# ATSAML21G18A register map
Vendor: Microchip Technology Inc.; Series: SAML21; File version: A
CPU: CM0+ r0p1, little endian, no MPU, no FPU, VTOR, 2 interrupt priority bits, 29 interrupts
Registers are 32-bit, read-write, reset 0x0 unless marked. A register's access mark holds for its fields unless they carry their own. Offsets are from the block's base; [hi:lo] are bit positions; {n}, {i} and the like mark numbered series; 'fields as' and 'values as' point back to an identical list.

## EVSYS — Event System Interface
Base 0x43000000; register names take the prefix EVSYS_
0x00 CTRLA 8-bit — Control
  [0] SWRST wo — Software Reset
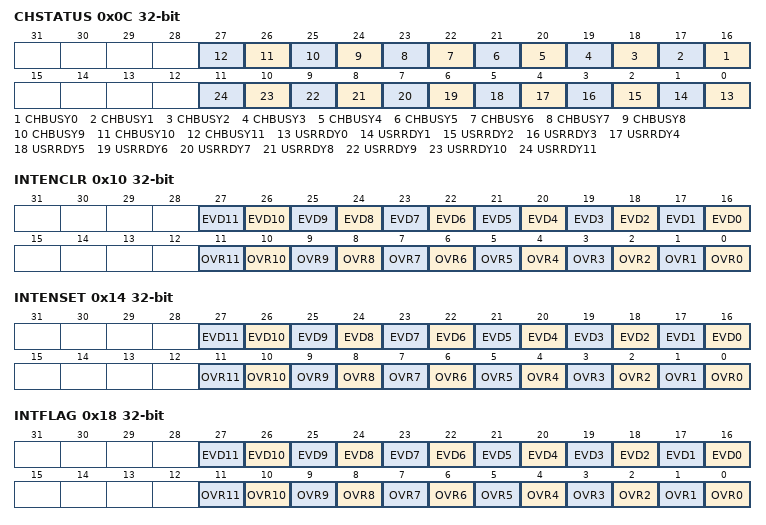
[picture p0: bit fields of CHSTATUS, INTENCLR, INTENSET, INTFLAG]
0x0C CHSTATUS ro — Channel Status
  [n+16] CHBUSY{n} (n=0..11) — Channel {n} Busy
  [n] USRRDY{n} (n=0..11) — Channel {n} User Ready
0x10 INTENCLR — Interrupt Enable Clear
  [n+16] EVD{n} (n=0..11) — Channel {n} Event Detection Interrupt Enable
  [n] OVR{n} (n=0..11) — Channel {n} Overrun Interrupt Enable
0x14 INTENSET — Interrupt Enable Set
  fields as INTENCLR
0x18 INTFLAG — Interrupt Flag Status and Clear
  [n+16] EVD{n} (n=0..11) — Channel {n} Event Detection
  [n] OVR{n} (n=0..11) — Channel {n} Overrun
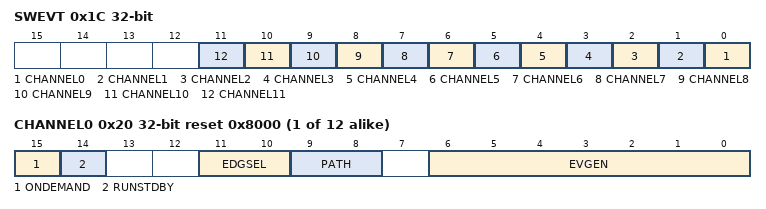
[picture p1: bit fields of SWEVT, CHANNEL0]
0x1C SWEVT wo — Software Event
  [n] CHANNEL{n} (n=0..11) — Channel {n} Software Selection
{0x20+4i} CHANNEL{i} (i=0..11) reset 0x8000 — Channel n
  [15] ONDEMAND — Generic Clock On Demand
  [14] RUNSTDBY — Run in standby
  [11:10] EDGSEL — Edge Detection Selection
    0=NO_EVT_OUTPUT (No event output when using the resynchronized or synchronous path); 1=RISING_EDGE (Event detection only on the rising edge of the signal from the event generator when using the resynchronized or synchronous path); 2=FALLING_EDGE (Event detection only on the falling edge of the signal from the event generator when using the resynchronized or synchronous path); 3=BOTH_EDGES (Event detection on rising and falling edges of the signal from the event generator when using the resynchronized or synchronous path)
  [9:8] PATH — Path Selection
    0=SYNCHRONOUS (Synchronous path); 1=RESYNCHRONIZED (Resynchronized path); 2=ASYNCHRONOUS (Asynchronous path)
  [6:0] EVGEN — Event Generator Selection
{0x80+4i} USER{i} (i=0..44) — User Multiplexer n
  [4:0] CHANNEL — Channel Event Selection

## GCLK — Generic Clock Generator
Base 0x40001800; register names take the prefix GCLK_
0x00 CTRLA 8-bit — Control
  [0] SWRST — Software Reset
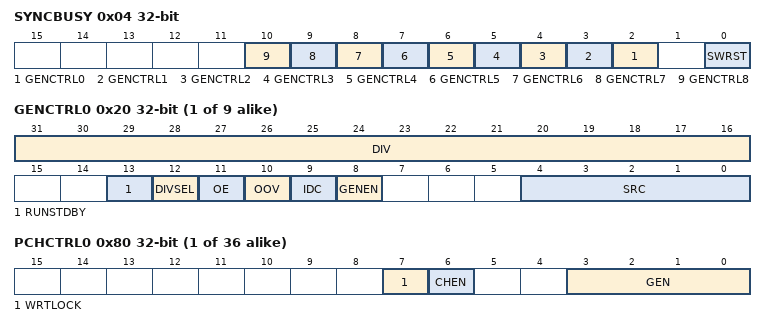
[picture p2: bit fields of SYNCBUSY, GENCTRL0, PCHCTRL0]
0x04 SYNCBUSY ro — Synchronization Busy
  [n+2] GENCTRL{n} (n=0..8) — Generic Clock Generator Control {n} Synchronization Busy bits
    1=GCLK0 (Generic clock generator 0); 2=GCLK1 (Generic clock generator 1); 4=GCLK2 (Generic clock generator 2); 8=GCLK3 (Generic clock generator 3); 16=GCLK4 (Generic clock generator 4); 32=GCLK5 (Generic clock generator 5); 64=GCLK6 (Generic clock generator 6); 128=GCLK7 (Generic clock generator 7); 0x100=GCLK8 (Generic clock generator 8)
  [0] SWRST — Software Reset Synchroniation Busy bit
{0x20+4i} GENCTRL{i} (i=0..8) — Generic Clock Generator Control
  [31:16] DIV — Division Factor
  [13] RUNSTDBY — Run in Standby
  [12] DIVSEL — Divide Selection
  [11] OE — Output Enable
  [10] OOV — Output Off Value
  [9] IDC — Improve Duty Cycle
  [8] GENEN — Generic Clock Generator Enable
  [4:0] SRC — Source Select
    0=XOSC (XOSC oscillator output); 1=GCLKIN (Generator input pad); 2=GCLKGEN1 (Generic clock generator 1 output); 3=OSCULP32K (OSCULP32K oscillator output); 4=OSC32K (OSC32K oscillator output); 5=XOSC32K (XOSC32K oscillator output); 6=OSC16M (OSC16M oscillator output); 7=DFLL48M (DFLL48M output); 8=DPLL96M (DPLL96M output)
{0x80+4i} PCHCTRL{i} (i=0..35) — Peripheral Clock Control
  [7] WRTLOCK — Write Lock
  [6] CHEN — Channel Enable
  [3:0] GEN — Generic Clock Generator
    {v}=GCLK{v} (Generic clock generator {v}) (v=0..8)

## MCLK — Main Clock
Base 0x40000400; register names take the prefix MCLK_
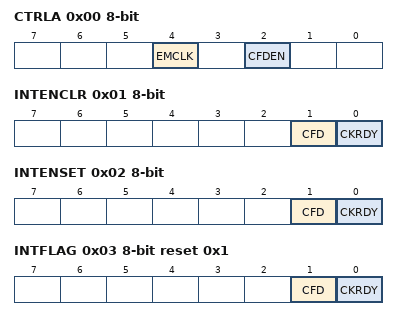
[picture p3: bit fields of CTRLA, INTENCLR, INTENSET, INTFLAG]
0x00 CTRLA 8-bit — Control A
  [4] EMCLK — Emergency Clock Select
  [2] CFDEN — Clock Failure Detector Enable
0x01 INTENCLR 8-bit — Interrupt Enable Clear
  [1] CFD — Clock Failure Detector Interrupt Enable
  [0] CKRDY — Clock Ready Interrupt Enable
0x02 INTENSET 8-bit — Interrupt Enable Set
  fields as INTENCLR
0x03 INTFLAG 8-bit reset 0x1 — Interrupt Flag Status and Clear
  [1] CFD — Clock Failure Detector
  [0] CKRDY — Clock Ready
0x04 CPUDIV 8-bit reset 0x1 — CPU Clock Division
  [7:0] CPUDIV — CPU Clock Division Factor
    1=DIV1 (Divide by 1); 2=DIV2 (Divide by 2); 4=DIV4 (Divide by 4); 8=DIV8 (Divide by 8); 16=DIV16 (Divide by 16); 32=DIV32 (Divide by 32); 64=DIV64 (Divide by 64); 128=DIV128 (Divide by 128)
0x05 LPDIV 8-bit reset 0x1 — Low-Power Clock Division
  [7:0] LPDIV — Low-Power Clock Division Factor
    values as CPUDIV.CPUDIV
0x06 BUPDIV 8-bit reset 0x1 — Backup Clock Division
  [7:0] BUPDIV — Backup Clock Division Factor
    values as CPUDIV.CPUDIV
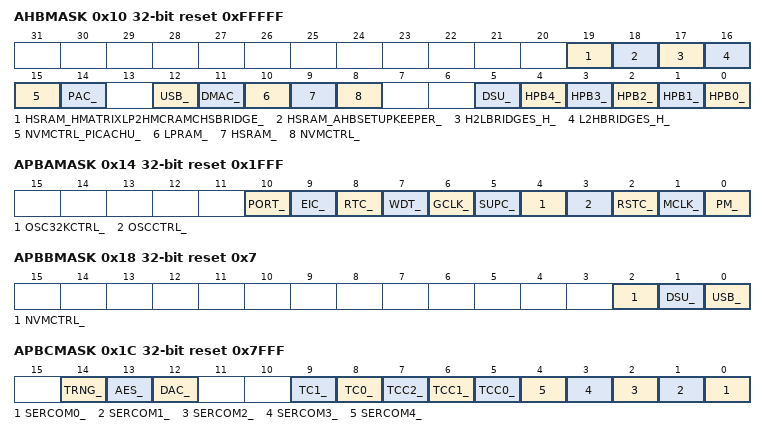
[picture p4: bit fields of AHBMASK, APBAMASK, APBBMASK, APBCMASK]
0x10 AHBMASK reset 0xFFFFF
  [19] HSRAM_HMATRIXLP2HMCRAMCHSBRIDGE_ — HSRAM_HMATRIXLP2HMCRAMCHSBRIDGE AHB Clock Mask
  [18] HSRAM_AHBSETUPKEEPER_ — HSRAM_AHBSETUPKEEPER AHB Clock Mask
  [17] H2LBRIDGES_H_ — H2LBRIDGES_H AHB Clock Mask
  [16] L2HBRIDGES_H_ — L2HBRIDGES_H AHB Clock Mask
  [15] NVMCTRL_PICACHU_ — NVMCTRL_PICACHU AHB Clock Mask
  [14] PAC_ — PAC AHB Clock Mask
  [12] USB_ — USB AHB Clock Mask
  [11] DMAC_ — DMAC AHB Clock Mask
  [10] LPRAM_ — LPRAM AHB Clock Mask
  [9] HSRAM_ — HSRAM AHB Clock Mask
  [8] NVMCTRL_ — NVMCTRL AHB Clock Mask
  [5] DSU_ — DSU AHB Clock Mask
  [n] HPB{n}_ (n=0..4) — HPB{n} AHB Clock Mask
0x14 APBAMASK reset 0x1FFF
  [10] PORT_ — PORT APB Clock Enable
  [9] EIC_ — EIC APB Clock Enable
  [8] RTC_ — RTC APB Clock Enable
  [7] WDT_ — WDT APB Clock Enable
  [6] GCLK_ — GCLK APB Clock Enable
  [5] SUPC_ — SUPC APB Clock Enable
  [4] OSC32KCTRL_ — OSC32KCTRL APB Clock Enable
  [3] OSCCTRL_ — OSCCTRL APB Clock Enable
  [2] RSTC_ — RSTC APB Clock Enable
  [1] MCLK_ — MCLK APB Clock Enable
  [0] PM_ — PM APB Clock Enable
0x18 APBBMASK reset 0x7
  [2] NVMCTRL_ — NVMCTRL APB Clock Enable
  [1] DSU_ — DSU APB Clock Enable
  [0] USB_ — USB APB Clock Enable
0x1C APBCMASK reset 0x7FFF
  [14] TRNG_ — TRNG APB Clock Enable
  [13] AES_ — AES APB Clock Enable
  [12] DAC_ — DAC APB Clock Enable
  [9] TC1_ — TC1 APB Clock Enable
  [8] TC0_ — TC0 APB Clock Enable
  [7] TCC2_ — TCC2 APB Clock Enable
  [6] TCC1_ — TCC1 APB Clock Enable
  [5] TCC0_ — TCC0 APB Clock Enable
  [n] SERCOM{n}_ (n=0..4) — SERCOM{n} APB Clock Enable
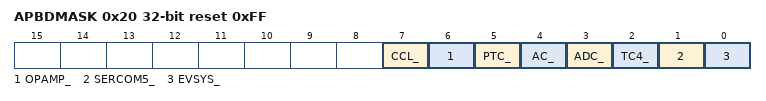
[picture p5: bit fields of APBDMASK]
0x20 APBDMASK reset 0xFF
  [7] CCL_ — CCL APB Clock Enable
  [6] OPAMP_ — OPAMP APB Clock Enable
  [5] PTC_ — PTC APB Clock Enable
  [4] AC_ — AC APB Clock Enable
  [3] ADC_ — ADC APB Clock Enable
  [2] TC4_ — TC4 APB Clock Enable
  [1] SERCOM5_ — SERCOM5 APB Clock Enable
  [0] EVSYS_ — EVSYS APB Clock Enable
0x24 APBEMASK reset 0x9
  [0] PAC_ — PAC APB Clock Enable

## Notices in the file
Copyright (c) 2018 Microchip Technology Inc.
SPDX-License-Identifier: Apache-2.0
Licensed under the Apache License, Version 2.0 (the "License");
you may not use this file except in compliance with the License.
You may obtain a copy of the License at
http://www.apache.org/licenses/LICENSE-2.0
Unless required by applicable law or agreed to in writing, software
distributed under the License is distributed on an "AS IS" BASIS,
WITHOUT WARRANTIES OR CONDITIONS OF ANY KIND, either express or implied.
See the License for the specific language governing permissions and
limitations under the License.
